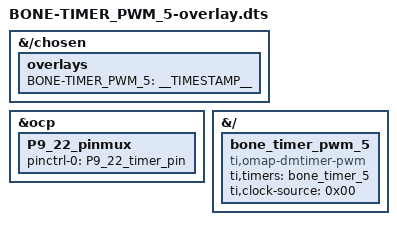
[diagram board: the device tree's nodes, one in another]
/*
 * Copyright (C) 2020 Deepak Khatri <deepaklorkhatri7@gmail.com>
 *
 * Virtual cape for /sys/devices/platform/bone_timer_pwm_5/ (only on BBAI)
 *
 * This program is free software; you can redistribute it and/or modify
 * it under the terms of the GNU General Public License version 2 as
 * published by the Free Software Foundation.
 */

/dts-v1/;
/plugin/;

/*
 * Update the default pinmux of the pins.
 * See these files for the phandles (&P9_* & &P8_*)
 * https://github.com/lorforlinux/BeagleBoard-DeviceTrees/blob/compatibility/src/arm/am335x-bone-common-univ.dtsi
 * https://github.com/lorforlinux/BeagleBoard-DeviceTrees/blob/compatibility/src/arm/am572x-bone-common-univ.dtsi
 */
&{/chosen} {
    overlays {
        BONE-TIMER_PWM_5 = __TIMESTAMP__;
    };
};

/*
* Update the default pinmux of the pins.
*/
&ocp {
    P9_22_pinmux { pinctrl-0 = <&P9_22_timer_pin>; };    /* PWM A */
};

// See these files for the definition
// https://github.com/lorforlinux/BeagleBoard-DeviceTrees/blob/compatibility/src/arm/bbai-bone-buses.dtsi
// https://github.com/lorforlinux/BeagleBoard-DeviceTrees/blob/compatibility/src/arm/bbb-bone-buses.dtsi
&{/} {
	bone_timer_pwm_5 {
		compatible = "ti,omap-dmtimer-pwm";
		#pwm-cells = <3>;
		ti,timers = <&bone_timer_5>;
		//ti,prescaler = <0>;		/* 0 thru 7 */
		ti,clock-source = <0x00>;	/* timer_sys_ck */
		//ti,clock-source = <0x01>;	/* timer_32k_ck */
	};
};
